# nrf54h20_enga_application register map
Vendor: Nordic Semiconductor; Series: nRF54h; File version: 1
CPU: CM33 r0p4, little endian, MPU, FPU, 3 interrupt priority bits, 480 interrupts, 4 SAU regions
Registers are 32-bit, read-write, reset 0x0 unless marked. A register's access mark holds for its fields unless they carry their own. Offsets are from the block's base; [hi:lo] are bit positions; 'fields as' and 'values as' point back to an identical list.

## GLOBAL_TBM_NS — Trace buffer monitor 0
Base 0xBF003000
Same registers: GLOBAL_TBM_S 0xBF003000 (alternate view of GLOBAL_TBM_NS)
0x00 TASKS_START wo — Start counter
  [0] TASKS_START
    1=Trigger task
0x04 TASKS_STOP wo — Stop counter, clear counter value
  [0] TASKS_STOP
    1=Trigger task
0x08 TASKS_FLUSH wo — Stop counter, keep current counter value
  [0] TASKS_FLUSH
    1=Trigger task
0x100 EVENTS_HALFFULL — Counter value equals half-full
  [0] EVENTS_HALFFULL
    0=NotGenerated (Event not generated); 1=Generated (Event generated)
0x104 EVENTS_FULL — Counter value equals full
  [0] EVENTS_FULL
    values as EVENTS_HALFFULL.EVENTS_HALFFULL
0x108 EVENTS_FLUSH — Counter stopped due to flush
  [0] EVENTS_FLUSH
    values as EVENTS_HALFFULL.EVENTS_HALFFULL
0x200 SHORTS — Shortcuts between local events and tasks
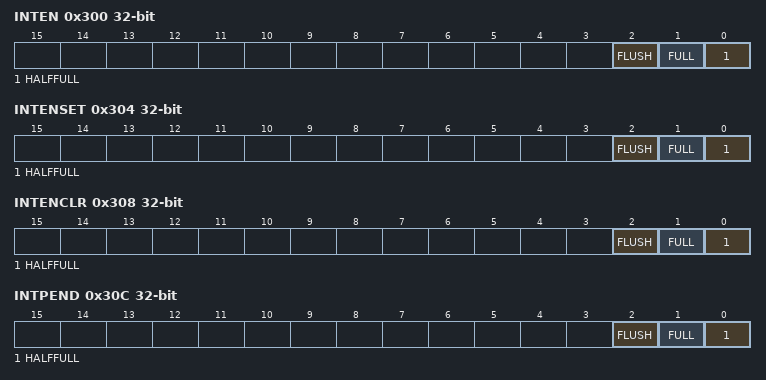
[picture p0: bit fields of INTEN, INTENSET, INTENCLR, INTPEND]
0x300 INTEN — Enable or disable interrupt
  [all] fields
    0=Disabled; 1=Enabled
  [2] FLUSH — Enable or disable interrupt for event FLUSH
  [1] FULL — Enable or disable interrupt for event FULL
  [0] HALFFULL — Enable or disable interrupt for event HALFFULL
0x304 INTENSET — Enable interrupt
  [all] fields
    on read: 0=Disabled (Read: Disabled); 1=Enabled (Read: Enabled) | on write: 1=Set (Enable)
  [2] FLUSH — Write '1' to enable interrupt for event FLUSH
  [1] FULL — Write '1' to enable interrupt for event FULL
  [0] HALFFULL — Write '1' to enable interrupt for event HALFFULL
0x308 INTENCLR — Disable interrupt
  [all] fields
    on read: 0=Disabled (Read: Disabled); 1=Enabled (Read: Enabled) | on write: 1=Clear (Disable)
  [2] FLUSH — Write '1' to disable interrupt for event FLUSH
  [1] FULL — Write '1' to disable interrupt for event FULL
  [0] HALFFULL — Write '1' to disable interrupt for event HALFFULL
0x30C INTPEND ro — Pending interrupts
  [all] fields
    on read: 0=NotPending (Read: Not pending); 1=Pending (Read: Pending)
  [2] FLUSH — Read pending status of interrupt for event FLUSH
  [1] FULL — Read pending status of interrupt for event FULL
  [0] HALFFULL — Read pending status of interrupt for event HALFFULL
0x400 BUFFERSIZE reset 0x1FF — System RAM trace buffer total size in bytes
  [11:0] BUFFERSIZE — Must only be configured in STOP mode. Must be multiple of 16 bytes to make half-buffer size always 64 bit word aligned. BUFFERSIZE LSB byte always fixed as 0xF to 16 bytes boundary. Minimum BUFFERSIZE value 0x00F i.e. 16 bytes, maximum value 0xFFF i.e. 4096 bytes.
    15=Min (16 bytes); 0xFFF=Max (4096 bytes)
0x404 COUNT ro — Counter current value
  [11:0] COUNT

## GLOBAL_USBHS_NS — USBHS 0
Base 0x4F086000
Same registers: GLOBAL_USBHS_S 0x5F086000
0x00 TASKS_START wo — Start the USB peripheral.
  [0] TASKS_START
    1=Trigger task
0x100 EVENTS_CORE — Event indicating that interrupt triggered at USBHS core
  [0] EVENTS_CORE
    0=NotGenerated (Event not generated); 1=Generated (Event generated)
0x300 INTEN — Enable or disable interrupt
  [0] CORE — Enable or disable interrupt for event CORE
    0=Disabled; 1=Enabled
0x304 INTENSET — Enable interrupt
  [0] CORE — Write '1' to enable interrupt for event CORE
    on read: 0=Disabled (Read: Disabled); 1=Enabled (Read: Enabled) | on write: 1=Set (Enable)
0x308 INTENCLR — Disable interrupt
  [0] CORE — Write '1' to disable interrupt for event CORE
    on read: 0=Disabled (Read: Disabled); 1=Enabled (Read: Enabled) | on write: 1=Clear (Disable)
0x30C INTPEND ro — Pending interrupts
  [0] CORE — Read pending status of interrupt for event CORE
    on read: 0=NotPending (Read: Not pending); 1=Pending (Read: Pending)
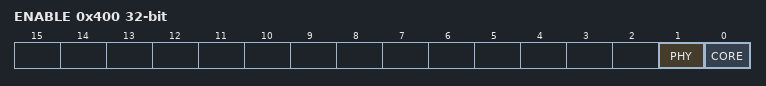
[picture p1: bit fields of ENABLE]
0x400 ENABLE — Enable USB peripheral.
  [1] PHY — Enable USB PHY
    0=Disabled (USB PHY disabled.); 1=Enabled (USB PHY enabled.)
  [0] CORE — Enable USB Controller
    0=Disabled (USB Controller disabled.); 1=Enabled (USB Controller enabled.)
